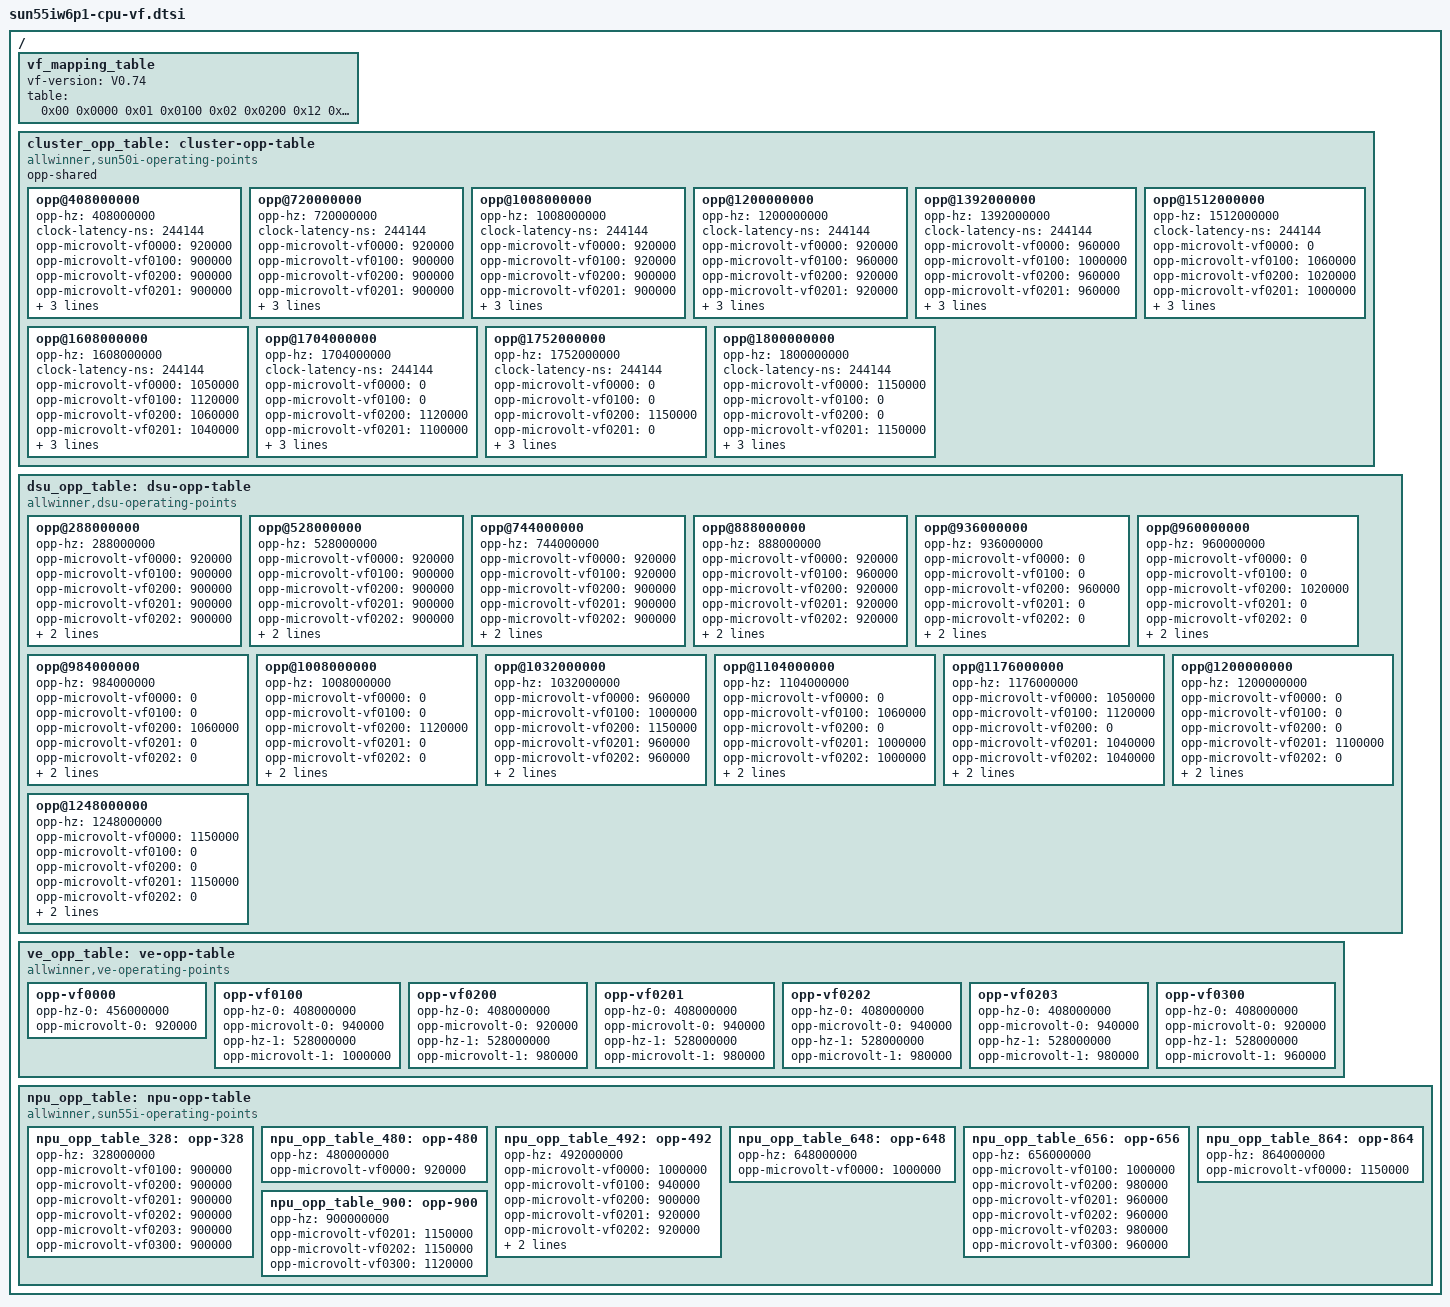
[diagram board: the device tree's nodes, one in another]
/* SPDX-License-Identifier: GPL-2.0-or-later */
/{
	vf_mapping_table: vf_mapping_table {
		vf-version = "V0.74";
		table = <
			0x00 0x0000
			0x01 0x0100
			0x02 0x0200
			0x12 0x0201
			0x22 0x0202
			0x32 0x0203
			0x03 0x0300
			>;
	};

	cluster_opp_table: cluster-opp-table {
		compatible = "allwinner,sun50i-operating-points";
		opp-shared;

		opp@408000000 {
			opp-hz = /bits/ 64 <408000000>;
			clock-latency-ns = <244144>; /* 8 32k periods */
			opp-microvolt-vf0000 = <920000>;
			opp-microvolt-vf0100 = <900000>;
			opp-microvolt-vf0200 = <900000>;
			opp-microvolt-vf0201 = <900000>;
			opp-microvolt-vf0202 = <900000>;
			opp-microvolt-vf0203 = <900000>;
			opp-microvolt-vf0300 = <900000>;
		};

		opp@720000000 {
			opp-hz = /bits/ 64 <720000000>;
			clock-latency-ns = <244144>; /* 8 32k periods */
			opp-microvolt-vf0000 = <920000>;
			opp-microvolt-vf0100 = <900000>;
			opp-microvolt-vf0200 = <900000>;
			opp-microvolt-vf0201 = <900000>;
			opp-microvolt-vf0202 = <900000>;
			opp-microvolt-vf0203 = <900000>;
			opp-microvolt-vf0300 = <900000>;
		};

		opp@1008000000 {
			opp-hz = /bits/ 64 <1008000000>;
			clock-latency-ns = <244144>; /* 8 32k periods */
			opp-microvolt-vf0000 = <920000>;
			opp-microvolt-vf0100 = <920000>;
			opp-microvolt-vf0200 = <900000>;
			opp-microvolt-vf0201 = <900000>;
			opp-microvolt-vf0202 = <900000>;
			opp-microvolt-vf0203 = <900000>;
			opp-microvolt-vf0300 = <900000>;
		};

		opp@1200000000 {
			opp-hz = /bits/ 64 <1200000000>;
			clock-latency-ns = <244144>; /* 8 32k periods */
			opp-microvolt-vf0000 = <920000>;
			opp-microvolt-vf0100 = <960000>;
			opp-microvolt-vf0200 = <920000>;
			opp-microvolt-vf0201 = <920000>;
			opp-microvolt-vf0202 = <920000>;
			opp-microvolt-vf0203 = <920000>;
			opp-microvolt-vf0300 = <900000>;
		};

		opp@1392000000 {
			opp-hz = /bits/ 64 <1392000000>;
			clock-latency-ns = <244144>; /* 8 32k periods */
			opp-microvolt-vf0000 = <960000>;
			opp-microvolt-vf0100 = <1000000>;
			opp-microvolt-vf0200 = <960000>;
			opp-microvolt-vf0201 = <960000>;
			opp-microvolt-vf0202 = <960000>;
			opp-microvolt-vf0203 = <960000>;
			opp-microvolt-vf0300 = <940000>;
		};

		opp@1512000000 {
			opp-hz = /bits/ 64 <1512000000>;
			clock-latency-ns = <244144>; /* 8 32k periods */
			opp-microvolt-vf0000 = <0>;
			opp-microvolt-vf0100 = <1060000>;
			opp-microvolt-vf0200 = <1020000>;
			opp-microvolt-vf0201 = <1000000>;
			opp-microvolt-vf0202 = <1000000>;
			opp-microvolt-vf0203 = <1020000>;
			opp-microvolt-vf0300 = <980000>;
		};

		opp@1608000000 {
			opp-hz = /bits/ 64 <1608000000>;
			clock-latency-ns = <244144>; /* 8 32k periods */
			opp-microvolt-vf0000 = <1050000>;
			opp-microvolt-vf0100 = <1120000>;
			opp-microvolt-vf0200 = <1060000>;
			opp-microvolt-vf0201 = <1040000>;
			opp-microvolt-vf0202 = <1040000>;
			opp-microvolt-vf0203 = <1060000>;
			opp-microvolt-vf0300 = <1020000>;
		};

		opp@1704000000 {
			opp-hz = /bits/ 64 <1704000000>;
			clock-latency-ns = <244144>; /* 8 32k periods */
			opp-microvolt-vf0000 = <0>;
			opp-microvolt-vf0100 = <0>;
			opp-microvolt-vf0200 = <1120000>;
			opp-microvolt-vf0201 = <1100000>;
			opp-microvolt-vf0202 = <0>;
			opp-microvolt-vf0203 = <0>;
			opp-microvolt-vf0300 = <1080000>;
		};

		opp@1752000000 {
			opp-hz = /bits/ 64 <1752000000>;
			clock-latency-ns = <244144>; /* 8 32k periods */
			opp-microvolt-vf0000 = <0>;
			opp-microvolt-vf0100 = <0>;
			opp-microvolt-vf0200 = <1150000>;
			opp-microvolt-vf0201 = <0>;
			opp-microvolt-vf0202 = <0>;
			opp-microvolt-vf0203 = <0>;
			opp-microvolt-vf0300 = <0>;
		};

		opp@1800000000 {
			opp-hz = /bits/ 64 <1800000000>;
			clock-latency-ns = <244144>; /* 8 32k periods */
			opp-microvolt-vf0000 = <1150000>;
			opp-microvolt-vf0100 = <0>;
			opp-microvolt-vf0200 = <0>;
			opp-microvolt-vf0201 = <1150000>;
			opp-microvolt-vf0202 = <0>;
			opp-microvolt-vf0203 = <0>;
			opp-microvolt-vf0300 = <1120000>;
		};
	};

	dsu_opp_table: dsu-opp-table {
		compatible = "allwinner,dsu-operating-points";

		opp@288000000 {
			opp-hz = /bits/ 64 <288000000>;
			opp-microvolt-vf0000 = <920000>;
			opp-microvolt-vf0100 = <900000>;
			opp-microvolt-vf0200 = <900000>;
			opp-microvolt-vf0201 = <900000>;
			opp-microvolt-vf0202 = <900000>;
			opp-microvolt-vf0203 = <900000>;
			opp-microvolt-vf0300 = <900000>;
		};

		opp@528000000 {
			opp-hz = /bits/ 64 <528000000>;
			opp-microvolt-vf0000 = <920000>;
			opp-microvolt-vf0100 = <900000>;
			opp-microvolt-vf0200 = <900000>;
			opp-microvolt-vf0201 = <900000>;
			opp-microvolt-vf0202 = <900000>;
			opp-microvolt-vf0203 = <900000>;
			opp-microvolt-vf0300 = <900000>;
		};

		opp@744000000 {
			opp-hz = /bits/ 64 <744000000>;
			opp-microvolt-vf0000 = <920000>;
			opp-microvolt-vf0100 = <920000>;
			opp-microvolt-vf0200 = <900000>;
			opp-microvolt-vf0201 = <900000>;
			opp-microvolt-vf0202 = <900000>;
			opp-microvolt-vf0203 = <900000>;
			opp-microvolt-vf0300 = <900000>;
		};

		opp@888000000 {
			opp-hz = /bits/ 64 <888000000>;
			opp-microvolt-vf0000 = <920000>;
			opp-microvolt-vf0100 = <960000>;
			opp-microvolt-vf0200 = <920000>;
			opp-microvolt-vf0201 = <920000>;
			opp-microvolt-vf0202 = <920000>;
			opp-microvolt-vf0203 = <920000>;
			opp-microvolt-vf0300 = <900000>;
		};

		opp@936000000 {
			opp-hz = /bits/ 64 <936000000>;
			opp-microvolt-vf0000 = <0>;
			opp-microvolt-vf0100 = <0>;
			opp-microvolt-vf0200 = <960000>;
			opp-microvolt-vf0201 = <0>;
			opp-microvolt-vf0202 = <0>;
			opp-microvolt-vf0203 = <0>;
			opp-microvolt-vf0300 = <0>;
		};

		opp@960000000 {
			opp-hz = /bits/ 64 <960000000>;
			opp-microvolt-vf0000 = <0>;
			opp-microvolt-vf0100 = <0>;
			opp-microvolt-vf0200 = <1020000>;
			opp-microvolt-vf0201 = <0>;
			opp-microvolt-vf0202 = <0>;
			opp-microvolt-vf0203 = <0>;
			opp-microvolt-vf0300 = <0>;
		};

		opp@984000000 {
			opp-hz = /bits/ 64 <984000000>;
			opp-microvolt-vf0000 = <0>;
			opp-microvolt-vf0100 = <0>;
			opp-microvolt-vf0200 = <1060000>;
			opp-microvolt-vf0201 = <0>;
			opp-microvolt-vf0202 = <0>;
			opp-microvolt-vf0203 = <0>;
			opp-microvolt-vf0300 = <0>;
		};


		opp@1008000000 {
			opp-hz = /bits/ 64 <1008000000>;
			opp-microvolt-vf0000 = <0>;
			opp-microvolt-vf0100 = <0>;
			opp-microvolt-vf0200 = <1120000>;
			opp-microvolt-vf0201 = <0>;
			opp-microvolt-vf0202 = <0>;
			opp-microvolt-vf0203 = <0>;
			opp-microvolt-vf0300 = <0>;
		};

		opp@1032000000 {
			opp-hz = /bits/ 64 <1032000000>;
			opp-microvolt-vf0000 = <960000>;
			opp-microvolt-vf0100 = <1000000>;
			opp-microvolt-vf0200 = <1150000>;
			opp-microvolt-vf0201 = <960000>;
			opp-microvolt-vf0202 = <960000>;
			opp-microvolt-vf0203 = <960000>;
			opp-microvolt-vf0300 = <940000>;
		};

		opp@1104000000 {
			opp-hz = /bits/ 64 <1104000000>;
			opp-microvolt-vf0000 = <0>;
			opp-microvolt-vf0100 = <1060000>;
			opp-microvolt-vf0200 = <0>;
			opp-microvolt-vf0201 = <1000000>;
			opp-microvolt-vf0202 = <1000000>;
			opp-microvolt-vf0203 = <1020000>;
			opp-microvolt-vf0300 = <980000>;
		};


		opp@1176000000 {
			opp-hz = /bits/ 64 <1176000000>;
			opp-microvolt-vf0000 = <1050000>;
			opp-microvolt-vf0100 = <1120000>;
			opp-microvolt-vf0200 = <0>;
			opp-microvolt-vf0201 = <1040000>;
			opp-microvolt-vf0202 = <1040000>;
			opp-microvolt-vf0203 = <1060000>;
			opp-microvolt-vf0300 = <1020000>;
		};

		opp@1200000000 {
			opp-hz = /bits/ 64 <1200000000>;
			opp-microvolt-vf0000 = <0>;
			opp-microvolt-vf0100 = <0>;
			opp-microvolt-vf0200 = <0>;
			opp-microvolt-vf0201 = <1100000>;
			opp-microvolt-vf0202 = <0>;
			opp-microvolt-vf0203 = <0>;
			opp-microvolt-vf0300 = <1080000>;
		};

		opp@1248000000 {
			opp-hz = /bits/ 64 <1248000000>;
			opp-microvolt-vf0000 = <1150000>;
			opp-microvolt-vf0100 = <0>;
			opp-microvolt-vf0200 = <0>;
			opp-microvolt-vf0201 = <1150000>;
			opp-microvolt-vf0202 = <0>;
			opp-microvolt-vf0203 = <0>;
			opp-microvolt-vf0300 = <1120000>;
		};
	};

	ve_opp_table: ve-opp-table {
		compatible = "allwinner,ve-operating-points";

		opp-vf0000 {
			opp-hz-0 = /bits/ 64 <456000000>;
			opp-microvolt-0 = <920000>;
		};
		opp-vf0100 {
			opp-hz-0 = /bits/ 64 <408000000>;
			opp-microvolt-0 = <940000>;
			opp-hz-1 = /bits/ 64 <528000000>;
			opp-microvolt-1 = <1000000>;
		};
		opp-vf0200 {
			opp-hz-0 = /bits/ 64 <408000000>;
			opp-microvolt-0 = <920000>;
			opp-hz-1 = /bits/ 64 <528000000>;
			opp-microvolt-1 = <980000>;
		};
		opp-vf0201 {
			opp-hz-0 = /bits/ 64 <408000000>;
			opp-microvolt-0 = <940000>;
			opp-hz-1 = /bits/ 64 <528000000>;
			opp-microvolt-1 = <980000>;
		};
		opp-vf0202 {
			opp-hz-0 = /bits/ 64 <408000000>;
			opp-microvolt-0 = <940000>;
			opp-hz-1 = /bits/ 64 <528000000>;
			opp-microvolt-1 = <980000>;
		};
		opp-vf0203 {
			opp-hz-0 = /bits/ 64 <408000000>;
			opp-microvolt-0 = <940000>;
			opp-hz-1 = /bits/ 64 <528000000>;
			opp-microvolt-1 = <980000>;
		};
		opp-vf0300 {
			opp-hz-0 = /bits/ 64 <408000000>;
			opp-microvolt-0 = <920000>;
			opp-hz-1 = /bits/ 64 <528000000>;
			opp-microvolt-1 = <960000>;
		};
	};

	npu_opp_table: npu-opp-table {
		compatible = "allwinner,sun55i-operating-points";

		npu_opp_table_328: opp-328 {
			opp-hz = <328000000>;
			opp-microvolt-vf0100 = <900000>;
			opp-microvolt-vf0200 = <900000>;
			opp-microvolt-vf0201 = <900000>;
			opp-microvolt-vf0202 = <900000>;
			opp-microvolt-vf0203 = <900000>;
			opp-microvolt-vf0300 = <900000>;
		};

		npu_opp_table_480: opp-480 {
			opp-hz = <480000000>;
			opp-microvolt-vf0000 = <920000>;
		};

		npu_opp_table_492: opp-492 {
			opp-hz = <492000000>;
			opp-microvolt-vf0000 = <1000000>;
			opp-microvolt-vf0100 = <940000>;
			opp-microvolt-vf0200 = <900000>;
			opp-microvolt-vf0201 = <920000>;
			opp-microvolt-vf0202 = <920000>;
			opp-microvolt-vf0203 = <920000>;
			opp-microvolt-vf0300 = <920000>;
		};

		npu_opp_table_648: opp-648 {
			opp-hz = <648000000>;
			opp-microvolt-vf0000 = <1000000>;
		};

		npu_opp_table_656: opp-656 {
			opp-hz = <656000000>;
			opp-microvolt-vf0100 = <1000000>;
			opp-microvolt-vf0200 = <980000>;
			opp-microvolt-vf0201 = <960000>;
			opp-microvolt-vf0202 = <960000>;
			opp-microvolt-vf0203 = <980000>;
			opp-microvolt-vf0300 = <960000>;
		};

		npu_opp_table_864: opp-864 {
			opp-hz = <864000000>;
			opp-microvolt-vf0000 = <1150000>;
		};

		npu_opp_table_900: opp-900 {
			opp-hz = <900000000>;
			opp-microvolt-vf0201 = <1150000>;
			opp-microvolt-vf0202 = <1150000>;
			opp-microvolt-vf0300 = <1120000>;
		};
	};
};
